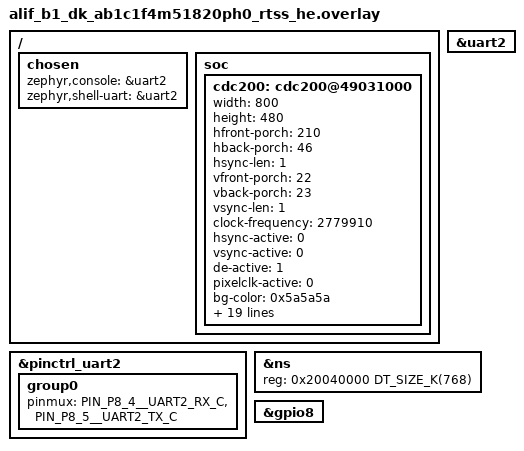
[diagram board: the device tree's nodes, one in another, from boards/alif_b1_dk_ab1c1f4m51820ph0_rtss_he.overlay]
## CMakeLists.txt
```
cmake_minimum_required(VERSION 3.20.0)

find_package(Zephyr REQUIRED HINTS $ENV{ZEPHYR_BASE})
project(display_cdc200_test)

target_sources(app PRIVATE
	src/main.c
	src/display_common.c
)
```

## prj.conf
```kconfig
CONFIG_ZTEST=y
CONFIG_ZTEST_STACK_SIZE=8192
CONFIG_MAIN_STACK_SIZE=4096

# Display subsystem + CDC200 driver
CONFIG_DISPLAY=y
CONFIG_MIPI_DSI=n

# Heap for buffer allocations
CONFIG_HEAP_MEM_POOL_SIZE=32768
CONFIG_SYS_HEAP_AUTO=y

# Logging
CONFIG_LOG=y
CONFIG_PRINTK=y
CONFIG_STDOUT_CONSOLE=y
CONFIG_DISPLAY_LOG_LEVEL_INF=y
```

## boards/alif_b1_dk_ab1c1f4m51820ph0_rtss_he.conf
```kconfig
CONFIG_FB_USES_DTCM_REGION=y
```

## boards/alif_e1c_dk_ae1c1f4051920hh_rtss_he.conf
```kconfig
# Copyright (C) Alif Semiconductor - All Rights Reserved.
# Use, distribution and modification of this code is permitted under the
# terms stated in the Alif Semiconductor Software License Agreement
#
# You should have received a copy of the Alif Semiconductor Software
# License Agreement with this file. If not, please write to:
# contact@alifsemi.com, or visit: https://alifsemi.com/license

CONFIG_FB_USES_DTCM_REGION=y
```

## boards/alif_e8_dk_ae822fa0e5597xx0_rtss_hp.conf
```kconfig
# Copyright (C) Alif Semiconductor - All Rights Reserved.
# Use, distribution and modification of this code is permitted under the
# terms stated in the Alif Semiconductor Software License Agreement
#
# You should have received a copy of the Alif Semiconductor Software
# License Agreement with this file. If not, please write to:
# contact@alifsemi.com, or visit: https://alifsemi.com/license

CONFIG_HEAP_MEM_POOL_SIZE=81920
```

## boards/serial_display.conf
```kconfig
CONFIG_MIPI_DSI=y
```

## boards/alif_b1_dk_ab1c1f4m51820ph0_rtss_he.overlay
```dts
/* Copyright (C) Alif Semiconductor - All Rights Reserved.
 * Use, distribution and modification of this code is permitted under the
 * terms stated in the Alif Semiconductor Software License Agreement
 *
 * You should have received a copy of the Alif Semiconductor Software
 * License Agreement with this file. If not, please write to:
 * contact@alifsemi.com, or visit: https://alifsemi.com/license
 *
 */

/ {
	chosen {
		zephyr,console = &uart2;
		zephyr,shell-uart = &uart2;
	};
};

&pinctrl_uart2 {
	group0 {
		pinmux = <PIN_P8_4__UART2_RX_C>,
			 <PIN_P8_5__UART2_TX_C>;
	};
};

&uart2 {
	status = "okay";
};

ns: &ns {
	status = "okay";
	reg = <0x20040000 DT_SIZE_K(768)>;
};

gpio8: &gpio8 {
	status = "okay";
};

/ {
	soc {
		cdc200: cdc200@49031000 {
	    width = <800>;
	    height = <480>;
	    hfront-porch = <210>;
		hback-porch = <46>;
	    hsync-len = <1>;
	    vfront-porch = <22>;
	    vback-porch = <23>;
	    vsync-len = <1>;
	    clock-frequency = <2779910>;
			hsync-active = <0>;
			vsync-active = <0>;
			de-active = <1>;
			pixelclk-active = <0>;
			bg-color = <0x5a5a5a>;
			enable-l1 = <1>;
			pixel-fmt-l1 = "rgb-565";
	    def-back-color-l1 = <0x00ff00>;
			win-x0-l1 = <0>;
			win-y0-l1 = <0>;
			//win-x1-l1 = <480>;
			win-x1-l1 = <800>;
	    win-y1-l1 = <480>;
			//win-y1-l1 = <800>;
			blend-factor1-l1 = <4>;
			blend-factor2-l1 = <5>;
			const-alpha-l1 = <0x7f>;
	    enable-l2 = <0>;
	    pixel-fmt-l2 = "argb-8888";
	    win-x0-l2 = <500>;
	    win-y0-l2 = <0>;
	    win-x1-l2 = <800>;
	    win-y1-l2 = <68>;
	    blend-factor1-l2 = <4>;
	    blend-factor2-l2 = <5>;
	    const-alpha-l2 = <0xaf>;
		};
	};
};
```

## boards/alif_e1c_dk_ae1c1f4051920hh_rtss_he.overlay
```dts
/* Copyright (C) Alif Semiconductor - All Rights Reserved.
 * Use, distribution and modification of this code is permitted under the
 * terms stated in the Alif Semiconductor Software License Agreement
 *
 * You should have received a copy of the Alif Semiconductor Software
 * License Agreement with this file. If not, please write to:
 * contact@alifsemi.com, or visit: https://alifsemi.com/license
 *
 */

/ {
	chosen {
		zephyr,console = &lpuart;
		zephyr,shell-uart = &lpuart;
	};
};

&uart2 {
	status = "disabled";
};

&lpuart {
	status = "okay";
};

ns: &ns {
	status = "okay";
};
```

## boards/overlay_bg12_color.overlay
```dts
/* Overlay: Background color = 0x002824
 * Visual check: Display background should appear as configured
 */

&cdc200 {
	bg-color = <0x002824>;
	enable-l1 = <0>;
	def-back-color-l1 = <0x005048>;
	enable-l2 = <0>;
	def-back-color-l2 = <0x00ffe7>;
	const-alpha-l1 = <0x7f>;
	const-alpha-l2 = <0xaf>;
};
```

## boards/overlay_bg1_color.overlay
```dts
/* Overlay: Background color = Red (0xFF0000)
 * Visual check: Display background should appear red
 */

&cdc200 {
	bg-color = <0xFF0000>;
	enable-l1 = <0>;
	def-back-color-l1 = <0x00ff00>;
	enable-l2 = <0>;
};
```

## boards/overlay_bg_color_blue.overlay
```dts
/* Overlay: Background color = Blue (0x0000FF)
 * Visual check: Display background should appear blue
 * Build: west build -b <board> <test_path> \
 *          -- -DDTC_OVERLAY_FILE=boards/<board>.overlay;boards/overlay_bg_color_blue.overlay
 */

&cdc200 {
	bg-color = <0x0000FF>;
	def-back-color-l1 = <0x000000>;
	enable-l1 = <0>;
	enable-l2 = <0>;
};
```

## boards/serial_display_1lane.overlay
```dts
#include <dt-bindings/misc/alif_aipm_common.h>

/ {
	soc {
		cdc200: cdc200@49031000 {
			width = <320>;
			hfront-porch = <46>;
			hback-porch = <16>;
			hsync-len = <14>;

			height = <480>;
			vfront-porch = <2>;
			vback-porch = <2>;
			vsync-len = <2>;

			hsync-active = <0>;
			vsync-active = <0>;
			de-active = <0>;
			pixelclk-active = <1>;

			clock-frequency = <11547360>;

			bg-color = <0>;
			enable-l1 = <1>;
			pixel-fmt-l1 = "rgb-565";
			def-back-color-l1 = <0>;
			win-x0-l1 = <0>;
			win-y0-l1 = <0>;
			win-x1-l1 = <320>;
			win-y1-l1 = <480>;
			blend-factor1-l1 = <4>;
			blend-factor2-l1 = <5>;
			const-alpha-l1 = <0xff>;
			enable-l2 = <0>;
			pixel-fmt-l2 = "undefined";
			win-x0-l2 = <0>;
			win-y0-l2 = <0>;
			win-x1-l2 = <0>;
			win-y1-l2 = <0>;
			blend-factor1-l2 = <6>;
			blend-factor2-l2 = <7>;
			const-alpha-l2 = <0xff>;
		};
	};
};

&mipi_dsi {
	//dpi-video-pattern-gen = "vertical-color-bar";
	//dpi-video-pattern-gen = "horizontal-color-bar";
	//dpi-video-pattern-gen = "vertical-bit-error-rate";
	status = "okay";
};

&ili9488 {
	status = "okay";
};

ns: &ns {
	status = "okay";
};

&gpio8 {
	status = "okay";
};

&aipm_run_default {
	phy-pwr-gating = <(ALIF_PHY_GATE_LDO_MASK |
			ALIF_PHY_GATE_MIPI_TX_DPHY_MASK |
			ALIF_PHY_GATE_MIPI_RX_DPHY_MASK |
			ALIF_PHY_GATE_MIPI_PLL_DPHY_MASK)>;
	ip-clock-gating = <(ALIF_IP_CLK_GATE_CDC200_MASK |
			ALIF_IP_CLK_GATE_MIPI_DSI_MASK |
			ALIF_IP_CLK_GATE_GPU_MASK)>;
};
```

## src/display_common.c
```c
/* Copyright (C) Alif Semiconductor - All Rights Reserved.
 * Use, distribution and modification of this code is permitted under the
 * terms stated in the Alif Semiconductor Software License Agreement
 *
 * You should have received a copy of the Alif Semiconductor Software
 * License Agreement with this file. If not, please write to:
 * contact@alifsemi.com, or visit: https://alifsemi.com/license
 */

#include <string.h>
#include <zephyr/cache.h>
#include "display_common.h"

const struct device *display_dev;

void display_suite_before(void *fixture)
{
	ARG_UNUSED(fixture);

	display_dev = DEVICE_DT_GET(DISPLAY_DEVICE_NODE);
	zassert_not_null(display_dev, "Display device handle is NULL");
	zassert_true(device_is_ready(display_dev),
		     "Display device %s not ready", display_dev->name);

#ifdef CONFIG_MIPI_DSI
	{
		const struct device *panel = DEVICE_DT_GET(DT_ALIAS(panel));
		const struct device *dsi = DEVICE_DT_GET(DT_ALIAS(mipi_dsi));
		int ret;

		zassert_true(device_is_ready(panel),
			     "MIPI panel %s not ready "
			     "(enable reset/backlight GPIOs in the overlay)",
			     panel->name);
		zassert_true(device_is_ready(dsi),
			     "MIPI-DSI host %s not ready", dsi->name);

		/*
		 * Panel init runs in command mode. Video mode is what
		 * streams the CDC200 framebuffer over the DSI link.
		 * Without this the panel stays black.
		 */
		ret = dsi_dw_set_mode(dsi, DSI_DW_VIDEO_MODE);
		zassert_equal(ret, 0,
			      "dsi_dw_set_mode(VIDEO) failed: %d", ret);
	}
#endif

	/*
	 * CDC200 init only programs registers; scan-out starts here.
	 * display_blanking_off() on CDC200 is a no-op (-ENOTSUP).
	 */
	cdc200_set_enable(display_dev, true);
}
void display_fb_fill_word_noflush(uint8_t *fb_addr, size_t fb_size,
			  int pixel_size, uint32_t color)
{
	if (pixel_size == 2) {
		uint16_t *p = (uint16_t *)fb_addr;
		size_t count = fb_size / 2;
		uint16_t c = (uint16_t)color;

		for (size_t i = 0; i < count; i++) {
			p[i] = c;
		}
	} else if (pixel_size == 4) {
		uint32_t *p = (uint32_t *)fb_addr;
		size_t count = fb_size / 4;

		for (size_t i = 0; i < count; i++) {
			p[i] = color;
		}
	} else {
		size_t count = fb_size / pixel_size;

		for (size_t i = 0; i < count; i++) {
			memcpy(fb_addr + (i * pixel_size), &color, pixel_size);
		}
	}
}

void display_fb_fill_word(uint8_t *fb_addr, size_t fb_size,
			  int pixel_size, uint32_t color)
{
	display_fb_fill_word_noflush(fb_addr, fb_size, pixel_size, color);
	sys_cache_data_flush_range(fb_addr, fb_size);
}

void display_fb_fill_memcpy_noflush(uint8_t *fb_addr, size_t fb_size,
			    int pixel_size, uint32_t color)
{
	size_t count = fb_size / pixel_size;

	for (size_t i = 0; i < count; i++) {
		memcpy(fb_addr + (i * pixel_size), &color, pixel_size);
	}
}

void display_fb_fill_memcpy(uint8_t *fb_addr, size_t fb_size,
			    int pixel_size, uint32_t color)
{
	display_fb_fill_memcpy_noflush(fb_addr, fb_size, pixel_size, color);
	sys_cache_data_flush_range(fb_addr, fb_size);
}

void display_clear_to_white(const struct device *dev)
{
	struct cdc200_fb_desc fb_desc;
	struct cdc200_display_caps caps;
	uint32_t color;
	int pixel_size;

	cdc200_get_capabilities(dev, &caps);

	/* Skip if layer 0 is disabled */
	if (!caps.layer[0].layer_en) {
		return;
	}

	/* Get framebuffer for layer 0 */
	cdc200_get_framebuffer(dev, 0, &fb_desc);

	if (fb_desc.fb_addr == NULL || fb_desc.fb_size == 0) {
		return;
	}

	/* Get pixel size */
	pixel_size = display_get_pixel_size(caps.layer[0].current_pixel_format);
	zassert_true(pixel_size > 0, "Unsupported pixel format: %d",
		     caps.layer[0].current_pixel_format);
	color = display_solid_color(caps.layer[0].current_pixel_format,
				    DISPLAY_COLOR_WHITE);

	/* Fill framebuffer with white */
	display_fb_fill_word(fb_desc.fb_addr, fb_desc.fb_size, pixel_size, color);
}

int display_get_pixel_size(enum display_pixel_format fmt)
{
	switch (fmt) {
	case PIXEL_FORMAT_ARGB_8888:
		return CDC200_PIXEL_SIZE_ARGB8888;
	case PIXEL_FORMAT_RGB_888:
		return CDC200_PIXEL_SIZE_RGB888;
	case PIXEL_FORMAT_RGB_565:
		return CDC200_PIXEL_SIZE_RGB565;
	default:
		return 0;
	}
}

uint32_t display_solid_color(enum display_pixel_format fmt,
			     enum display_test_color color)
{
	static const uint32_t colors_argb8888[DISPLAY_COLOR_COUNT] = {
		RED_ARGB8888, GREEN_ARGB8888, BLUE_ARGB8888,
		WHITE_ARGB8888, BLACK_ARGB8888,
	};
	static const uint32_t colors_rgb888[DISPLAY_COLOR_COUNT] = {
		RED_RGB888, GREEN_RGB888, BLUE_RGB888,
		WHITE_RGB888, BLACK_RGB888,
	};
	static const uint32_t colors_rgb565[DISPLAY_COLOR_COUNT] = {
		RED_RGB565, GREEN_RGB565, BLUE_RGB565,
		WHITE_RGB565, BLACK_RGB565,
	};

	if (color >= DISPLAY_COLOR_COUNT) {
		return 0;
	}

	switch (fmt) {
	case PIXEL_FORMAT_ARGB_8888:
		return colors_argb8888[color];
	case PIXEL_FORMAT_RGB_888:
		return colors_rgb888[color];
	case PIXEL_FORMAT_RGB_565:
	default:
		return colors_rgb565[color];
	}
}

void display_fill_buffer_solid(uint8_t *buf, size_t buf_size,
			       enum display_pixel_format fmt,
			       uint32_t color)
{
	int pixel_size = display_get_pixel_size(fmt);

	if (pixel_size == 0) {
		return;
	}

	switch (fmt) {
	case PIXEL_FORMAT_ARGB_8888:
		for (size_t idx = 0; idx < buf_size; idx += 4) {
			*((uint32_t *)(buf + idx)) = color;
		}
		break;
	case PIXEL_FORMAT_RGB_888:
		for (size_t idx = 0; idx < buf_size; idx += 3) {
			*(buf + idx + 2) = (color >> 16) & 0xff;
			*(buf + idx + 1) = (color >> 8) & 0xff;
			*(buf + idx + 0) = (color >> 0) & 0xff;
		}
		break;
	case PIXEL_FORMAT_RGB_565:
		for (size_t idx = 0; idx < buf_size; idx += 2) {
			*(buf + idx + 1) = (color >> 8) & 0xFFu;
			*(buf + idx + 0) = (color >> 0) & 0xFFu;
		}
		break;
	default:
		break;
	}
}

uint8_t *display_alloc_buffer(size_t size)
{
	uint8_t *buf = k_malloc(size);

	zassert_not_null(buf, "Failed to allocate %zu byte buffer", size);
	return buf;
}

void display_free_buffer(uint8_t *buf)
{
	if (buf) {
		k_free(buf);
	}
}

const char *display_pixel_format_to_string(enum display_pixel_format fmt)
{
	switch (fmt) {
	case PIXEL_FORMAT_RGB_888:
		return "RGB_888";
	case PIXEL_FORMAT_MONO01:
		return "MONO01";
	case PIXEL_FORMAT_MONO10:
		return "MONO10";
	case PIXEL_FORMAT_ARGB_8888:
		return "ARGB_8888";
	case PIXEL_FORMAT_RGB_565:
		return "RGB_565";
	case PIXEL_FORMAT_BGR_565:
		return "BGR_565";
	default:
		return "UNKNOWN";
	}
}

const char *display_errno_to_string(int err)
{
	switch (err) {
	case 0:
		return "0 (SUCCESS)";
	case -EINVAL:
		return "-EINVAL";
	case -ENOMEM:
		return "-ENOMEM";
	case -ENOTSUP:
		return "-ENOTSUP";
	case -ENOSYS:
		return "-ENOSYS";
	case -EIO:
		return "-EIO";
	case -EACCES:
		return "-EACCES";
	case -EBUSY:
		return "-EBUSY";
	case -ETIMEDOUT:
		return "-ETIMEDOUT";
	default:
		return "UNKNOWN";
	}
}
```

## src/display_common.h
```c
/* Copyright (C) Alif Semiconductor - All Rights Reserved.
 * Use, distribution and modification of this code is permitted under the
 * terms stated in the Alif Semiconductor Software License Agreement
 *
 * You should have received a copy of the Alif Semiconductor Software
 * License Agreement with this file. If not, please write to:
 * contact@alifsemi.com, or visit: https://alifsemi.com/license
 */

#ifndef ALIF_DISPLAY_TEST_COMMON_H_
#define ALIF_DISPLAY_TEST_COMMON_H_

#include <zephyr/kernel.h>
#include <zephyr/device.h>
#include <zephyr/drivers/display.h>
#include <zephyr/drivers/display/cdc200.h>
#ifdef CONFIG_MIPI_DSI
#include <zephyr/drivers/mipi_dsi/dsi_dw.h>
#endif
#include <zephyr/logging/log.h>
#include <zephyr/ztest.h>
#include <stdint.h>

#include <soc_common.h>
#include <zephyr/cache.h>

#if defined(CONFIG_ENSEMBLE_GEN2)
#include <zephyr/drivers/gpio.h>
#endif

#define DISPLAY_DEVICE_NODE	DT_CHOSEN(zephyr_display)

/* Framebuffer write method selection */
#define DISPLAY_FB_WRITE_DIRECT	0
#define DISPLAY_FB_WRITE_API	1

/* Default to direct framebuffer write */
#ifndef DISPLAY_FB_WRITE_METHOD
#define DISPLAY_FB_WRITE_METHOD	DISPLAY_FB_WRITE_DIRECT
#endif

/* Color definitions for different pixel formats */
#define RED_ARGB8888		0x00ff0000
#define GREEN_ARGB8888		0x0000ff00
#define BLUE_ARGB8888		0x000000ff
#define WHITE_ARGB8888		0x00ffffff
#define BLACK_ARGB8888		0x00000000
#define RED_RGB888		0x00ff0000
#define GREEN_RGB888		0x0000ff00
#define BLUE_RGB888		0x000000ff
#define WHITE_RGB888		0x00ffffff
#define BLACK_RGB888		0x00000000
#define RED_RGB565		0xf800
#define GREEN_RGB565		0x07e0
#define BLUE_RGB565		0x001f
#define WHITE_RGB565		0xffff
#define BLACK_RGB565		0x0000

/* Pixel sizes for CDC200 */
#define CDC200_PIXEL_SIZE_ARGB8888	4
#define CDC200_PIXEL_SIZE_RGB888	3
#define CDC200_PIXEL_SIZE_RGB565	2

/* Named colors for display_solid_color() */
enum display_test_color {
	DISPLAY_COLOR_RED = 0,
	DISPLAY_COLOR_GREEN,
	DISPLAY_COLOR_BLUE,
	DISPLAY_COLOR_WHITE,
	DISPLAY_COLOR_BLACK,
	DISPLAY_COLOR_COUNT,
};

/* Shared device handle. */
extern const struct device *display_dev;

/* Suite hook: acquires + validates the display device. */
void display_suite_before(void *fixture);

/* Get pixel size in bytes for a given pixel format. */
int display_get_pixel_size(enum display_pixel_format fmt);

/* Packed solid color for the given pixel format. */
uint32_t display_solid_color(enum display_pixel_format fmt,
			     enum display_test_color color);

/* Fill a buffer with a solid color for the given pixel format. */
void display_fill_buffer_solid(uint8_t *buf, size_t buf_size,
			       enum display_pixel_format fmt,
			       uint32_t color);

/* Allocate a display buffer of the given size. Asserts if allocation fails. */
uint8_t *display_alloc_buffer(size_t size);

/* Free a display buffer. */
void display_free_buffer(uint8_t *buf);

/* Convert pixel format enum to readable string. */
const char *display_pixel_format_to_string(enum display_pixel_format fmt);

/* Convert errno code to readable string. */
const char *display_errno_to_string(int err);


/* Fast word-based framebuffer fill with no flush. */
void display_fb_fill_word_noflush(uint8_t *fb_addr, size_t fb_size,
				  int pixel_size, uint32_t color);

/* Per-pixel memcpy framebuffer fill with no flush. */
void display_fb_fill_memcpy_noflush(uint8_t *fb_addr, size_t fb_size,
				    int pixel_size, uint32_t color);

/* Fast word-based framebuffer fill (more efficient than per-pixel memcpy). */
void display_fb_fill_word(uint8_t *fb_addr, size_t fb_size,
			  int pixel_size, uint32_t color);

/* Per-pixel memcpy framebuffer fill (slower, used for benchmarking). */
void display_fb_fill_memcpy(uint8_t *fb_addr, size_t fb_size,
			    int pixel_size, uint32_t color);

/* Clear display to white color (cleanup function). */
void display_clear_to_white(const struct device *dev);

#endif /* ALIF_DISPLAY_TEST_COMMON_H_ */
```
